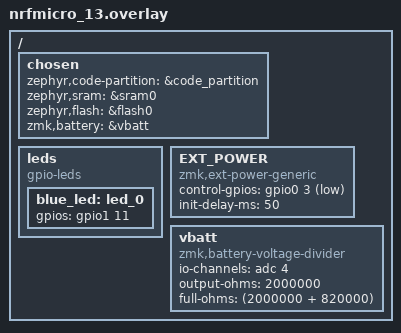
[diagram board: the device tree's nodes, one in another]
/ {
    chosen {
        zephyr,code-partition = &code_partition;
        zephyr,sram = &sram0;
        zephyr,flash = &flash0;
        zmk,battery = &vbatt;
    };

    leds {
        compatible = "gpio-leds";
        blue_led: led_0 {
            gpios = <&gpio1 11 GPIO_ACTIVE_HIGH>;
        };
    };
    EXT_POWER {
        compatible = "zmk,ext-power-generic";
        control-gpios = <&gpio0 3 GPIO_ACTIVE_LOW>;
        init-delay-ms = <50>;
    };
    vbatt:vbatt {
        compatible = "zmk,battery-voltage-divider";
        io-channels = <&adc 4>;
        output-ohms = <2000000>;
        full-ohms = <(2000000 + 820000)>;
    };
};
